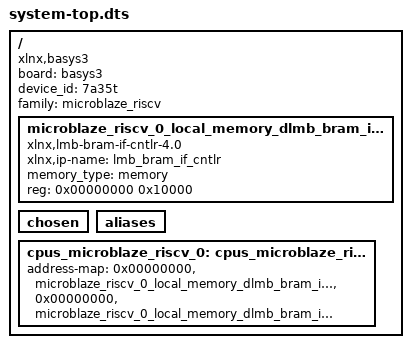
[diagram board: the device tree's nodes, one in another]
/dts-v1/;
#include "pl.dtsi"
/ {
	board = "basys3";
	compatible = "xlnx,basys3";
	device_id = "7a35t";
	#address-cells = <1>;
	#size-cells = <1>;
	family = "microblaze_riscv";
	microblaze_riscv_0_local_memory_dlmb_bram_if_cntlr_memory: memory@0 {
		compatible = "xlnx,lmb-bram-if-cntlr-4.0";
		xlnx,ip-name = "lmb_bram_if_cntlr";
		device_type = "memory";
		memory_type = "memory";
		reg = <0x00000000 0x10000>;
	};
	chosen {
	};
	aliases {
	};
	cpus_microblaze_riscv_0: cpus_microblaze_riscv@0 {
		address-map = <0x00000000 &microblaze_riscv_0_local_memory_dlmb_bram_if_cntlr_memory 0x00000000 0x10000>, 
			      <0x00000000 &microblaze_riscv_0_local_memory_dlmb_bram_if_cntlr 0x00000000 0x10000>;
		#ranges-address-cells = <0x1>;
		#ranges-size-cells = <0x1>;
	};
};
